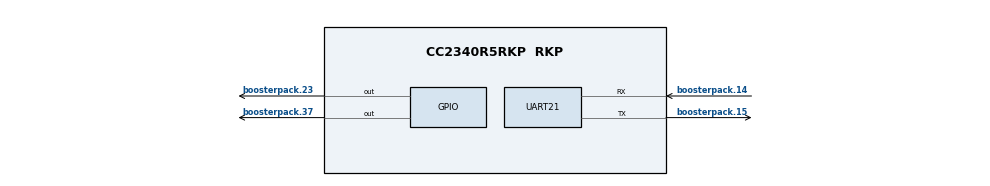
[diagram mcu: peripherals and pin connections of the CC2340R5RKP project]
/**
 * @cliArgs --board "/ti/boards/LP_EM_CC2340R5" --device "CC2340R5RKP" --part "Default" --package "RKP" --rtos "nortos" --product "simplelink_lowpower_f3_sdk@9.10.00.83"
 * @versions {"tool":"1.23.1+4034"}
 */

/**
 * Import the modules used in this configuration.
 */
const GPIO   = scripting.addModule("/ti/drivers/GPIO");
const GPIO1  = GPIO.addInstance();
const GPIO2  = GPIO.addInstance();
const Power  = scripting.addModule("/ti/drivers/Power");
const UART2  = scripting.addModule("/ti/drivers/UART2", {}, false);
const UART21 = UART2.addInstance();

/**
 * Write custom configuration values to the imported modules.
 */
GPIO1.$name              = "CONFIG_GPIO_SBL_BACKDOOR";
GPIO1.mode               = "Output";
GPIO1.initialOutputState = "High";
GPIO1.gpioPin.$assign    = "boosterpack.23";

GPIO2.$name           = "CONFIG_GPIO_SBL_RST";
GPIO2.gpioPin.$assign = "boosterpack.37";

const CCFG              = scripting.addModule("/ti/devices/CCFG", {}, false);
CCFG.ccfgTemplate.$name = "ti_devices_CCFG_CCFGCC23X0Template0";

UART21.$name              = "CONFIG_UART2_SBL";
UART21.enableNonblocking  = false;
UART21.uart.txPin.$assign = "boosterpack.15";
UART21.uart.rxPin.$assign = "boosterpack.14";

/**
 * Pinmux solution for unlocked pins/peripherals. This ensures that minor changes to the automatic solver in a future
 * version of the tool will not impact the pinmux you originally saw.  These lines can be completely deleted in order to
 * re-solve from scratch.
 */
UART21.uart.$suggestSolution              = "UART0";
UART21.uart.dmaTxChannel.$suggestSolution = "DMA_CH1";
UART21.uart.dmaRxChannel.$suggestSolution = "DMA_CH0";
